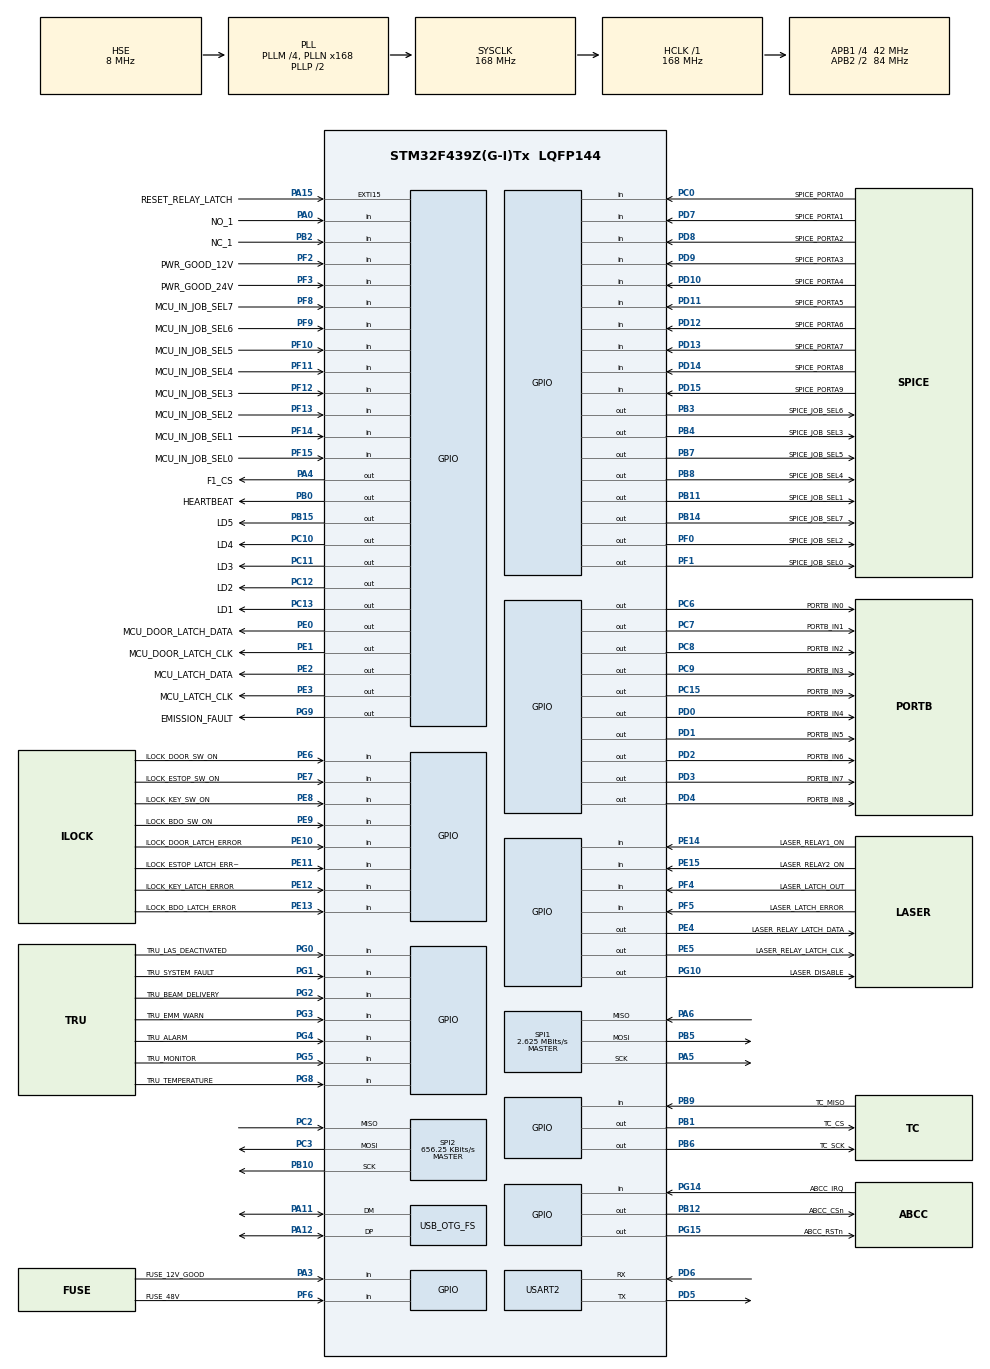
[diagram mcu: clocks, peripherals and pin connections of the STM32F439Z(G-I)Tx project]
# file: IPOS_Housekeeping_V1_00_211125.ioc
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Dma.Request0=USART2_RX
Dma.Request1=SPI2_RX
Dma.Request2=SPI2_TX
Dma.SPI2_RX.1.Direction=DMA_PERIPH_TO_MEMORY
Dma.SPI2_RX.1.FIFOMode=DMA_FIFOMODE_DISABLE
Dma.SPI2_RX.1.Instance=DMA1_Stream3
Dma.SPI2_RX.1.MemDataAlignment=DMA_MDATAALIGN_BYTE
Dma.SPI2_RX.1.MemInc=DMA_MINC_ENABLE
Dma.SPI2_RX.1.Mode=DMA_NORMAL
Dma.SPI2_RX.1.PeriphDataAlignment=DMA_PDATAALIGN_BYTE
Dma.SPI2_RX.1.PeriphInc=DMA_PINC_DISABLE
Dma.SPI2_RX.1.Priority=DMA_PRIORITY_LOW
Dma.SPI2_TX.2.Direction=DMA_MEMORY_TO_PERIPH
Dma.SPI2_TX.2.FIFOMode=DMA_FIFOMODE_DISABLE
Dma.SPI2_TX.2.Instance=DMA1_Stream4
Dma.SPI2_TX.2.MemDataAlignment=DMA_MDATAALIGN_BYTE
Dma.SPI2_TX.2.MemInc=DMA_MINC_ENABLE
Dma.SPI2_TX.2.Mode=DMA_NORMAL
Dma.SPI2_TX.2.PeriphDataAlignment=DMA_PDATAALIGN_BYTE
Dma.SPI2_TX.2.PeriphInc=DMA_PINC_DISABLE
Dma.SPI2_TX.2.Priority=DMA_PRIORITY_LOW
Dma.USART2_RX.0.Direction=DMA_PERIPH_TO_MEMORY
Dma.USART2_RX.0.FIFOMode=DMA_FIFOMODE_DISABLE
Dma.USART2_RX.0.Instance=DMA1_Stream5
Dma.USART2_RX.0.MemDataAlignment=DMA_MDATAALIGN_BYTE
Dma.USART2_RX.0.MemInc=DMA_MINC_ENABLE
Dma.USART2_RX.0.Mode=DMA_NORMAL
Dma.USART2_RX.0.PeriphDataAlignment=DMA_PDATAALIGN_BYTE
Dma.USART2_RX.0.PeriphInc=DMA_PINC_DISABLE
Dma.USART2_RX.0.Priority=DMA_PRIORITY_LOW
FREERTOS.Tasks01=default_task,24,128,default_app,Default,NULL,Dynamic,NULL,NULL
FREERTOS.configTOTAL_HEAP_SIZE=30 * 1024
FREERTOS.configUSE_NEWLIB_REENTRANT=1
Mcu.Family=STM32F4
Mcu.Name=STM32F439Z(G-I)Tx
Mcu.Package=LQFP144
NVIC.DMA1_Stream3_IRQn=true\:5\:0\:false\:false\:true\:true\:false\:true\:true
NVIC.DMA1_Stream4_IRQn=true\:5\:0\:false\:false\:true\:true\:false\:true\:true
NVIC.DMA1_Stream5_IRQn=true\:5\:0\:false\:false\:true\:true\:false\:true\:true
NVIC.EXTI15_10_IRQn=true\:5\:0\:false\:false\:true\:true\:true\:true\:true
NVIC.OTG_FS_IRQn=true\:5\:0\:false\:false\:true\:true\:true\:true\:true
NVIC.PriorityGroup=NVIC_PRIORITYGROUP_4
NVIC.SPI2_IRQn=true\:5\:0\:false\:false\:true\:true\:true\:true\:true
NVIC.TIM6_DAC_IRQn=true\:15\:0\:false\:false\:true\:false\:false\:true\:true
NVIC.TimeBase=TIM6_DAC_IRQn
NVIC.TimeBaseIP=TIM6
NVIC.USART2_IRQn=true\:5\:0\:false\:false\:true\:true\:true\:true\:true
PA0/WKUP.GPIO_Label=NO_1
PA0/WKUP.GPIO_PuPd=GPIO_PULLDOWN
PA0/WKUP.Signal=GPIO_Input
PA11.Mode=Device_Only
PA11.Signal=USB_OTG_FS_DM
PA12.Mode=Device_Only
PA12.Signal=USB_OTG_FS_DP
PA13.Mode=Serial_Wire
PA13.Signal=SYS_JTMS-SWDIO
PA14.Mode=Serial_Wire
PA14.Signal=SYS_JTCK-SWCLK
PA15.GPIO_Label=RESET_RELAY_LATCH
PA15.GPIO_ModeDefaultEXTI=GPIO_MODE_IT_FALLING
PA15.Signal=GPXTI15
PA3.GPIO_Label=FUSE_12V_GOOD
PA3.Signal=GPIO_Input
PA4.GPIO_Label=F1_CS
PA4.Signal=GPIO_Output
PA5.Mode=Full_Duplex_Master
PA5.Signal=SPI1_SCK
PA6.GPIO_PuPd=GPIO_PULLUP
PA6.Mode=Full_Duplex_Master
PA6.Signal=SPI1_MISO
PB0.GPIO_Label=HEARTBEAT
PB0.Signal=GPIO_Output
PB1.GPIO_Label=TC_CS
PB1.Signal=GPIO_Output
PB10.GPIO_PuPd=GPIO_NOPULL
PB10.Mode=Full_Duplex_Master
PB10.Signal=SPI2_SCK
PB11.GPIO_Label=SPICE_JOB_SEL1
PB11.Signal=GPIO_Output
PB12.GPIO_Label=ABCC_CSn
PB12.Signal=GPIO_Output
PB14.GPIO_Label=SPICE_JOB_SEL7
PB14.Signal=GPIO_Output
PB15.GPIO_Label=LD5
PB15.Signal=GPIO_Output
PB2/BOOT1.GPIO_Label=NC_1
PB2/BOOT1.GPIO_PuPd=GPIO_PULLDOWN
PB2/BOOT1.Signal=GPIO_Input
PB3.GPIO_Label=SPICE_JOB_SEL6
PB3.Signal=GPIO_Output
PB4.GPIO_Label=SPICE_JOB_SEL3
PB4.Signal=GPIO_Output
PB5.GPIO_PuPd=GPIO_PULLUP
PB5.Mode=Full_Duplex_Master
PB5.Signal=SPI1_MOSI
PB6.GPIO_Label=TC_SCK
PB6.Signal=GPIO_Output
PB7.GPIO_Label=SPICE_JOB_SEL5
PB7.Signal=GPIO_Output
PB8.GPIO_Label=SPICE_JOB_SEL4
PB8.Signal=GPIO_Output
PB9.GPIO_Label=TC_MISO
PB9.Signal=GPIO_Input
PC0.GPIO_Label=SPICE_PORTA0
PC0.GPIO_PuPd=GPIO_PULLUP
PC0.Signal=GPIO_Input
PC10.GPIO_Label=LD4
PC10.Signal=GPIO_Output
PC11.GPIO_Label=LD3
PC11.Signal=GPIO_Output
PC12.GPIO_Label=LD2
PC12.Signal=GPIO_Output
PC13.GPIO_Label=LD1
PC13.Signal=GPIO_Output
PC15/OSC32_OUT.GPIO_Label=PORTB_IN9
PC15/OSC32_OUT.Signal=GPIO_Output
PC2.GPIO_PuPd=GPIO_NOPULL
PC2.Mode=Full_Duplex_Master
PC2.Signal=SPI2_MISO
PC3.GPIO_PuPd=GPIO_NOPULL
PC3.Mode=Full_Duplex_Master
PC3.Signal=SPI2_MOSI
PC6.GPIO_Label=PORTB_IN0
PC6.GPIO_PuPd=GPIO_PULLUP
PC6.Signal=GPIO_Output
PC7.GPIO_Label=PORTB_IN1
PC7.Signal=GPIO_Output
PC8.GPIO_Label=PORTB_IN2
PC8.Signal=GPIO_Output
PC9.GPIO_Label=PORTB_IN3
PC9.Signal=GPIO_Output
PD0.GPIO_Label=PORTB_IN4
PD0.Signal=GPIO_Output
PD1.GPIO_Label=PORTB_IN5
PD1.Signal=GPIO_Output
PD10.GPIO_Label=SPICE_PORTA4
PD10.Signal=GPIO_Input
PD11.GPIO_Label=SPICE_PORTA5
PD11.Signal=GPIO_Input
PD12.GPIO_Label=SPICE_PORTA6
PD12.Signal=GPIO_Input
PD13.GPIO_Label=SPICE_PORTA7
PD13.Signal=GPIO_Input
PD14.GPIO_Label=SPICE_PORTA8
PD14.Signal=GPIO_Input
PD15.GPIO_Label=SPICE_PORTA9
PD15.Signal=GPIO_Input
PD2.GPIO_Label=PORTB_IN6
PD2.Signal=GPIO_Output
PD3.GPIO_Label=PORTB_IN7
PD3.Signal=GPIO_Output
PD4.GPIO_Label=PORTB_IN8
PD4.Signal=GPIO_Output
PD5.Mode=Asynchronous
PD5.Signal=USART2_TX
PD6.Mode=Asynchronous
PD6.Signal=USART2_RX
PD7.GPIO_Label=SPICE_PORTA1
PD7.Signal=GPIO_Input
PD8.GPIO_Label=SPICE_PORTA2
PD8.Signal=GPIO_Input
PD9.GPIO_Label=SPICE_PORTA3
PD9.Signal=GPIO_Input
PE0.GPIO_Label=MCU_DOOR_LATCH_DATA
PE0.Signal=GPIO_Output
PE1.GPIO_Label=MCU_DOOR_LATCH_CLK
PE1.Signal=GPIO_Output
PE10.GPIO_Label=ILOCK_DOOR_LATCH_ERROR
PE10.Signal=GPIO_Input
PE11.GPIO_Label=ILOCK_ESTOP_LATCH_ERROR
PE11.Signal=GPIO_Input
PE12.GPIO_Label=ILOCK_KEY_LATCH_ERROR
PE12.Signal=GPIO_Input
PE13.GPIO_Label=ILOCK_BDO_LATCH_ERROR
PE13.Signal=GPIO_Input
PE14.GPIO_Label=LASER_RELAY1_ON
PE14.Signal=GPIO_Input
PE15.GPIO_Label=LASER_RELAY2_ON
PE15.Signal=GPIO_Input
PE2.GPIO_Label=MCU_LATCH_DATA
PE2.Signal=GPIO_Output
PE3.GPIO_Label=MCU_LATCH_CLK
PE3.GPIO_PuPd=GPIO_PULLUP
PE3.GPIO_Speed=GPIO_SPEED_FREQ_LOW
PE3.PinState=GPIO_PIN_SET
PE3.Signal=GPIO_Output
PE4.GPIO_Label=LASER_RELAY_LATCH_DATA
PE4.Signal=GPIO_Output
PE5.GPIO_Label=LASER_RELAY_LATCH_CLK
PE5.GPIO_PuPd=GPIO_PULLUP
PE5.Signal=GPIO_Output
PE6.GPIO_Label=ILOCK_DOOR_SW_ON
PE6.Signal=GPIO_Input
PE7.GPIO_Label=ILOCK_ESTOP_SW_ON
PE7.Signal=GPIO_Input
PE8.GPIO_Label=ILOCK_KEY_SW_ON
PE8.Signal=GPIO_Input
PE9.GPIO_Label=ILOCK_BDO_SW_ON
PE9.Signal=GPIO_Input
PF0.GPIO_Label=SPICE_JOB_SEL2
PF0.Signal=GPIO_Output
PF1.GPIO_Label=SPICE_JOB_SEL0
PF1.Signal=GPIO_Output
PF10.GPIO_Label=MCU_IN_JOB_SEL5
PF10.Signal=GPIO_Input
PF11.GPIO_Label=MCU_IN_JOB_SEL4
PF11.Signal=GPIO_Input
PF12.GPIO_Label=MCU_IN_JOB_SEL3
PF12.Signal=GPIO_Input
PF13.GPIO_Label=MCU_IN_JOB_SEL2
PF13.Signal=GPIO_Input
PF14.GPIO_Label=MCU_IN_JOB_SEL1
PF14.Signal=GPIO_Input
PF15.GPIO_Label=MCU_IN_JOB_SEL0
PF15.Signal=GPIO_Input
PF2.GPIO_Label=PWR_GOOD_12V
PF2.Signal=GPIO_Input
PF3.GPIO_Label=PWR_GOOD_24V
PF3.Signal=GPIO_Input
PF4.GPIO_Label=LASER_LATCH_OUT
PF4.Signal=GPIO_Input
PF5.GPIO_Label=LASER_LATCH_ERROR
PF5.Signal=GPIO_Input
PF6.GPIO_Label=FUSE_48V
PF6.Signal=GPIO_Input
PF8.GPIO_Label=MCU_IN_JOB_SEL7
PF8.Signal=GPIO_Input
PF9.GPIO_Label=MCU_IN_JOB_SEL6
PF9.Signal=GPIO_Input
PG0.GPIO_Label=TRU_LAS_DEACTIVATED
PG0.Signal=GPIO_Input
PG1.GPIO_Label=TRU_SYSTEM_FAULT
PG1.Signal=GPIO_Input
PG10.GPIO_Label=LASER_DISABLE
PG10.Signal=GPIO_Output
PG13.Signal=ETH_TXD0
PG14.GPIO_Label=ABCC_IRQ
PG14.GPIO_PuPd=GPIO_NOPULL
PG14.Signal=GPIO_Input
PG15.GPIO_Label=ABCC_RSTn
PG15.Signal=GPIO_Output
PG2.GPIO_Label=TRU_BEAM_DELIVERY
PG2.Signal=GPIO_Input
PG3.GPIO_Label=TRU_EMM_WARN
PG3.Signal=GPIO_Input
PG4.GPIO_Label=TRU_ALARM
PG4.Signal=GPIO_Input
PG5.GPIO_Label=TRU_MONITOR
PG5.Signal=GPIO_Input
PG8.GPIO_Label=TRU_TEMPERATURE
PG8.Signal=GPIO_Input
PG9.GPIO_Label=EMISSION_FAULT
PG9.GPIO_PuPd=GPIO_NOPULL
PG9.Signal=GPIO_Output
PH0/OSC_IN.Mode=HSE-External-Oscillator
PH0/OSC_IN.Signal=RCC_OSC_IN
PH1/OSC_OUT.Mode=HSE-External-Oscillator
PH1/OSC_OUT.Signal=RCC_OSC_OUT
ProjectManager.HeapSize=0x200
ProjectManager.StackSize=0x400
ProjectManager.TargetToolchain=STM32CubeIDE
RCC.48MHZClocksFreq_Value=48000000
RCC.AHBFreq_Value=168000000
RCC.APB1CLKDivider=RCC_HCLK_DIV4
RCC.APB1Freq_Value=42000000
RCC.APB1TimFreq_Value=84000000
RCC.APB2CLKDivider=RCC_HCLK_DIV2
RCC.APB2Freq_Value=84000000
RCC.APB2TimFreq_Value=168000000
RCC.CortexFreq_Value=168000000
RCC.HCLKFreq_Value=168000000
RCC.HSE_VALUE=8000000
RCC.HSI_VALUE=16000000
RCC.LSE_VALUE=32768
RCC.PLLM=4
RCC.PLLN=168
RCC.PLLQ=7
RCC.SYSCLKFreq_VALUE=168000000
RCC.SYSCLKSource=RCC_SYSCLKSOURCE_PLLCLK
RCC.VCOOutputFreq_Value=336000000
SPI1.BaudRatePrescaler=SPI_BAUDRATEPRESCALER_32
SPI1.CalculateBaudRate=2.625 MBits/s
SPI1.Direction=SPI_DIRECTION_2LINES
SPI1.Mode=SPI_MODE_MASTER
SPI1.VirtualType=VM_MASTER
SPI2.BaudRatePrescaler=SPI_BAUDRATEPRESCALER_64
SPI2.CalculateBaudRate=656.25 KBits/s
SPI2.Direction=SPI_DIRECTION_2LINES
SPI2.Mode=SPI_MODE_MASTER
SPI2.VirtualType=VM_MASTER
USART2.VirtualMode=VM_ASYNC
USB_DEVICE.CLASS_NAME_FS=CDC
USB_DEVICE.USBD_MAX_STR_DESC_SIZ-CDC_FS=1024
USB_DEVICE.VirtualMode-CDC_FS=Cdc
USB_DEVICE.VirtualModeFS=Cdc_FS
USB_OTG_FS.VirtualMode=Device_Only
VP_FREERTOS_VS_CMSIS_V2.Mode=CMSIS_V2
VP_SYS_VS_tim6.Mode=TIM6
VP_USB_DEVICE_VS_USB_DEVICE_CDC_FS.Mode=CDC_FS
board=custom

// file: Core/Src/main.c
/* USER CODE BEGIN Header */
/**
  ******************************************************************************
  * @file           : main.c
  * @brief          : Main program body
  ******************************************************************************
  * @attention
  *
  * Copyright (c) 2025 STMicroelectronics.
  * All rights reserved.
  *
  * This software is licensed under terms that can be found in the LICENSE file
  * in the root directory of this software component.
  * If no LICENSE file comes with this software, it is provided AS-IS.
  *
  ******************************************************************************
  */
/* USER CODE END Header */
#include "main.h"
#include "cmsis_os.h"
#include "dma.h"
#include "spi.h"
#include "usart.h"
#include "usb_device.h"
#include "gpio.h"

/* USER CODE BEGIN Includes */
#include "protocol.h"   // for gUsbFlags
#include "inputs.h"
#include "abcc_api.h"
/* USER CODE END Includes */

void SystemClock_Config(void);
void MX_FREERTOS_Init(void);

/* USER CODE BEGIN 0 */

/*------------------------------------------------------------------------------
** ABCC_API_CbfUserInit()
** Place to take action based on ABCC module network type and firmware version.
** Calls ABCC_API_UserInitComplete() to indicate to the abcc_driver to continue.
**------------------------------------------------------------------------------
*/
void ABCC_API_CbfUserInit( ABCC_API_NetworkType iNetworkType, ABCC_API_FwVersionType iFirmwareVersion )
{
   ABCC_API_UserInitComplete();
   return;
}

void vApplicationStackOverflowHook(TaskHandle_t xTask, char *pcTaskName) {
    taskDISABLE_INTERRUPTS();
    __BKPT(0);
    for(;;);
}
void vApplicationMallocFailedHook(void) {
    taskDISABLE_INTERRUPTS();
    for(;;);   // Break here in debugger
}

/* USER CODE END 0 */

int main(void)
{

  /* MCU Configuration--------------------------------------------------------*/

  /* Reset of all peripherals, Initializes the Flash interface and the Systick. */
  HAL_Init();

  /* Configure the system clock */
  SystemClock_Config();

  /* Initialize all configured peripherals */
  MX_GPIO_Init();
  MX_DMA_Init();
  MX_USART2_UART_Init();
  MX_SPI1_Init();
  MX_SPI2_Init();
  /* USER CODE BEGIN 2 */

  reset_latches(); // clear any issues, if there is still a hardware fault the error will not clear

  /* USER CODE END 2 */

  /* Init scheduler */
  osKernelInitialize();  /* Call init function for freertos objects (in cmsis_os2.c) */
  MX_FREERTOS_Init();

  /* Start scheduler */
  osKernelStart();

  /* We should never get here as control is now taken by the scheduler */

  /* Infinite loop */
  while (1)
  {

  }
}

void SystemClock_Config(void)
{
  RCC_OscInitTypeDef RCC_OscInitStruct = {0};
  RCC_ClkInitTypeDef RCC_ClkInitStruct = {0};

  /** Configure the main internal regulator output voltage
  */
  __HAL_RCC_PWR_CLK_ENABLE();
  __HAL_PWR_VOLTAGESCALING_CONFIG(PWR_REGULATOR_VOLTAGE_SCALE1);

  /** Initializes the RCC Oscillators according to the specified parameters
  * in the RCC_OscInitTypeDef structure.
  */
  RCC_OscInitStruct.OscillatorType = RCC_OSCILLATORTYPE_HSE;
  RCC_OscInitStruct.HSEState = RCC_HSE_ON;
  RCC_OscInitStruct.PLL.PLLState = RCC_PLL_ON;
  RCC_OscInitStruct.PLL.PLLSource = RCC_PLLSOURCE_HSE;
  RCC_OscInitStruct.PLL.PLLM = 4;
  RCC_OscInitStruct.PLL.PLLN = 168;
  RCC_OscInitStruct.PLL.PLLP = RCC_PLLP_DIV2;
  RCC_OscInitStruct.PLL.PLLQ = 7;
  if (HAL_RCC_OscConfig(&RCC_OscInitStruct) != HAL_OK)
  {
    Error_Handler();
  }

  /** Initializes the CPU, AHB and APB buses clocks
  */
  RCC_ClkInitStruct.ClockType = RCC_CLOCKTYPE_HCLK|RCC_CLOCKTYPE_SYSCLK
                              |RCC_CLOCKTYPE_PCLK1|RCC_CLOCKTYPE_PCLK2;
  RCC_ClkInitStruct.SYSCLKSource = RCC_SYSCLKSOURCE_PLLCLK;
  RCC_ClkInitStruct.AHBCLKDivider = RCC_SYSCLK_DIV1;
  RCC_ClkInitStruct.APB1CLKDivider = RCC_HCLK_DIV4;
  RCC_ClkInitStruct.APB2CLKDivider = RCC_HCLK_DIV2;

  if (HAL_RCC_ClockConfig(&RCC_ClkInitStruct, FLASH_LATENCY_5) != HAL_OK)
  {
    Error_Handler();
  }
}

/* USER CODE BEGIN 4 */

// Interrupt callback (EXTI) or GPIO check

/* USER CODE END 4 */

void HAL_TIM_PeriodElapsedCallback(TIM_HandleTypeDef *htim)
{
  if (htim->Instance == TIM6)
  {
    HAL_IncTick();
  }
}

void Error_Handler(void)
{
  __disable_irq();
  while (1)
  {
  }
}

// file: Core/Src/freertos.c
/* USER CODE BEGIN Header */
/**
  ******************************************************************************
  * File Name          : freertos.c
  * Description        : Code for freertos applications
  ******************************************************************************
  * @attention
  *
  * Copyright (c) 2025 STMicroelectronics.
  * All rights reserved.
  *
  * This software is licensed under terms that can be found in the LICENSE file
  * in the root directory of this software component.
  * If no LICENSE file comes with this software, it is provided AS-IS.
  *
  ******************************************************************************
  */
/* USER CODE END Header */

#include "FreeRTOS.h"
#include "task.h"
#include "main.h"
#include "cmsis_os.h"

/* USER CODE BEGIN Includes */
#include "uart_master_task.h"
#include "master_link.h"
#include "stdio.h"
#include "stdbool.h"
#include "string.h"
#include "protocol.h"
#include "inputs.h"
/* USER CODE END Includes */

/* USER CODE BEGIN PD */
//#define USBBUF_MAXLEN 128
/* USER CODE END PD */

/* Definitions for default_task */
osThreadId_t default_taskHandle;
const osThreadAttr_t default_task_attributes = {
  .name = "default_task",
  .stack_size = 128 * 4,
  .priority = (osPriority_t) osPriorityNormal,
};

void default_app(void *argument);

extern void MX_USB_DEVICE_Init(void);
void MX_FREERTOS_Init(void); /* (MISRA C 2004 rule 8.1) */

void MX_FREERTOS_Init(void) {
  /* USER CODE BEGIN Init */

//	osThreadNew(UsbInitTask, NULL, &(const osThreadAttr_t){
//		.name = "usb_init_task",
//		.priority = osPriorityNormal,
//		.stack_size = 256
//	});

	extern void App_Start(void);
	App_Start();
  /* USER CODE END Init */

  /* Create the thread(s) */
  /* creation of default_task */
  default_taskHandle = osThreadNew(default_app, NULL, &default_task_attributes);

}

void default_app(void *argument)
{
  /* init code for USB_DEVICE */
  MX_USB_DEVICE_Init();
  for(;;)
  {
    osDelay(1);
  }
}
